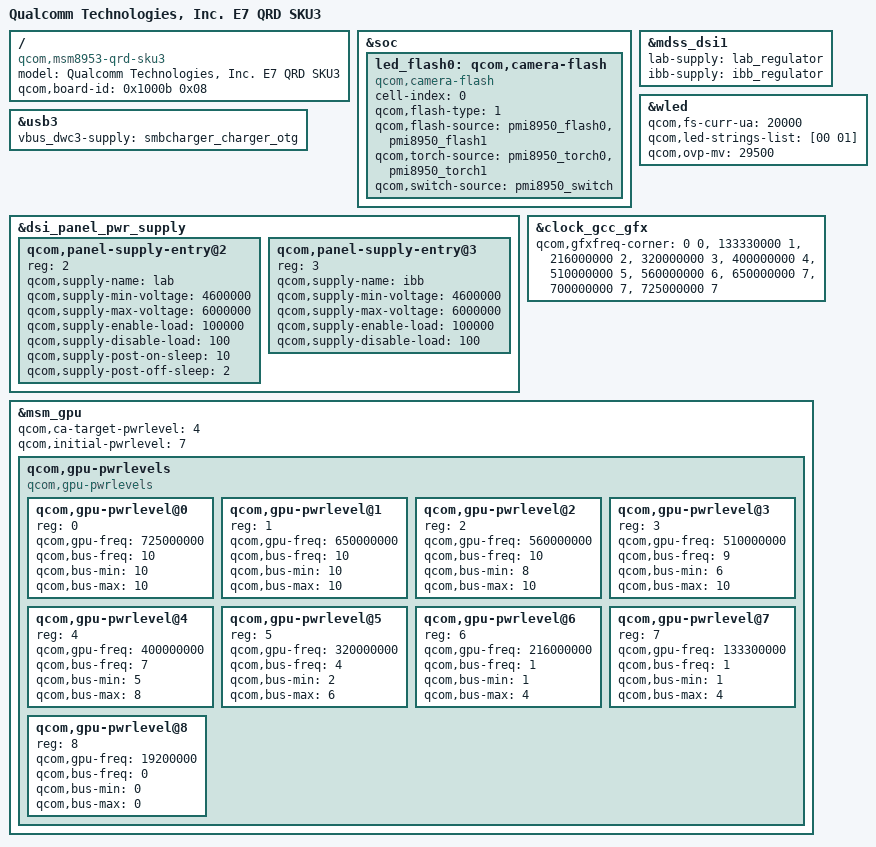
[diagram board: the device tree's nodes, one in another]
/*
 * Copyright (c) 2015-2017, The Linux Foundation. All rights reserved.
 * Copyright (C) 2019 XiaoMi, Inc.
 *
 * This program is free software; you can redistribute it and/or modify
 * it under the terms of the GNU General Public License version 2 and
 * only version 2 as published by the Free Software Foundation.
 *
 * This program is distributed in the hope that it will be useful,
 * but WITHOUT ANY WARRANTY; without even the implied warranty of
 * MERCHANTABILITY or FITNESS FOR A PARTICULAR PURPOSE.  See the
 * GNU General Public License for more details.
 */

/dts-v1/;

#include "msm8953.dtsi"
#include "msm-pmi8950.dtsi"

/ {
	model = "Qualcomm Technologies, Inc. E7 QRD SKU3";
	compatible = "qcom,msm8953-qrd-sku3",
		   "qcom,msm8953-qrd", "qcom,msm8953", "qcom,qrd";
	qcom,board-id= <0x1000b 0x08>;
};

&soc {
	led_flash0: qcom,camera-flash {
		cell-index = <0>;
		compatible = "qcom,camera-flash";
		qcom,flash-type = <1>;
		qcom,flash-source = <&pmi8950_flash0 &pmi8950_flash1>;
		qcom,torch-source = <&pmi8950_torch0 &pmi8950_torch1>;
		qcom,switch-source = <&pmi8950_switch>;
	};
};

#include "msm8953-qrd-sku3.dtsi"

&usb3 {
	vbus_dwc3-supply = <&smbcharger_charger_otg>;
};

&mdss_dsi1 {
	lab-supply = <&lab_regulator>;
	ibb-supply = <&ibb_regulator>;
};

&wled {
	qcom,fs-curr-ua = <20000>;
	qcom,led-strings-list = [00 01];
	qcom,ovp-mv = <29500>;
};

&dsi_panel_pwr_supply {
	qcom,panel-supply-entry@2 {
		reg = <2>;
		qcom,supply-name = "lab";
		qcom,supply-min-voltage = <4600000>;
		qcom,supply-max-voltage = <6000000>;
		qcom,supply-enable-load = <100000>;
		qcom,supply-disable-load = <100>;
		qcom,supply-post-on-sleep = <10>;
		qcom,supply-post-off-sleep = <2>;
	};

	qcom,panel-supply-entry@3 {
		reg = <3>;
		qcom,supply-name = "ibb";
		qcom,supply-min-voltage = <4600000>;
		qcom,supply-max-voltage = <6000000>;
		qcom,supply-enable-load = <100000>;
		qcom,supply-disable-load = <100>;
		/*qcom,supply-post-on-sleep = <10>;*/
	};
};

&clock_gcc_gfx {
	qcom,gfxfreq-corner =
		 <         0   0 >,
		 < 133330000   1 >,  /* Min SVS   */
		 < 216000000   2 >,  /* Low SVS   */
		 < 320000000   3 >,  /* SVS       */
		 < 400000000   4 >,  /* SVS Plus  */
		 < 510000000   5 >,  /* NOM       */
		 < 560000000   6 >,  /* Nom Plus  */
		 < 650000000   7 >,  /* Turbo     */
		 < 700000000   7 >,  /* Turbo     */
		 < 725000000   7 >;  /* Turbo     */
};

&msm_gpu {

	qcom,ca-target-pwrlevel = <4>;
	qcom,initial-pwrlevel = <7>;
	/delete-node/qcom,gpu-pwrlevels;

	/* Power levels */
	qcom,gpu-pwrlevels {
		#address-cells = <1>;
		#size-cells = <0>;

		compatible = "qcom,gpu-pwrlevels";
		/* TURBO LD0 */
		qcom,gpu-pwrlevel@0 {
			reg = <0>;
			qcom,gpu-freq = <725000000>;
			qcom,bus-freq = <10>;
			qcom,bus-min = <10>;
			qcom,bus-max = <10>;
		};

		/* TURBO */
		qcom,gpu-pwrlevel@1 {
			reg = <1>;
			qcom,gpu-freq = <650000000>;
			qcom,bus-freq = <10>;
			qcom,bus-min = <10>;
			qcom,bus-max = <10>;
		};

		/* NOM+ */
		qcom,gpu-pwrlevel@2 {
			reg = <2>;
			qcom,gpu-freq = <560000000>;
			qcom,bus-freq = <10>;
			qcom,bus-min = <8>;
			qcom,bus-max = <10>;
		};

		/* NOM */
		qcom,gpu-pwrlevel@3 {
			reg = <3>;
			qcom,gpu-freq = <510000000>;
			qcom,bus-freq = <9>;
			qcom,bus-min = <6>;
			qcom,bus-max = <10>;
		};

		/* SVS+ */
		qcom,gpu-pwrlevel@4 {
			reg = <4>;
			qcom,gpu-freq = <400000000>;
			qcom,bus-freq = <7>;
			qcom,bus-min = <5>;
			qcom,bus-max = <8>;
		};

		/* SVS */
		qcom,gpu-pwrlevel@5 {
			reg = <5>;
			qcom,gpu-freq = <320000000>;
			qcom,bus-freq = <4>;
			qcom,bus-min = <2>;
			qcom,bus-max = <6>;
		};

		/* Low SVS */
		qcom,gpu-pwrlevel@6 {
			reg = <6>;
			qcom,gpu-freq = <216000000>;
			qcom,bus-freq = <1>;
			qcom,bus-min = <1>;
			qcom,bus-max = <4>;
		};

		qcom,gpu-pwrlevel@7 {
			reg = <7>;
			qcom,gpu-freq = <133300000>;
			qcom,bus-freq = <1>;
			qcom,bus-min = <1>;
			qcom,bus-max = <4>;
		};
		/* XO */
		qcom,gpu-pwrlevel@8 {
			reg = <8>;
			qcom,gpu-freq = <19200000>;
			qcom,bus-freq = <0>;
			qcom,bus-min = <0>;
			qcom,bus-max = <0>;
		};
	};
}; 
